# HDSC_HC32L156JX register map
Vendor: HDSC Co.Ltd; Series: ARMCM0P; File version: 1.2
CPU: CM0 r0p0, little endian, no MPU, no FPU, 3 interrupt priority bits
Registers are 8-bit, read-write, reset 0x0 unless marked. A register's access mark holds for its fields unless they carry their own. Offsets are from the block's base; lines under a group give offsets from that group; [hi:lo] are bit positions; {n}, {i} and the like mark numbered series; 'fields as' and 'values as' point back to an identical list; <NAME> marks a mode.

## Memory map
0x40000000 FLASH size 0x10C
0x40000200 UID size 0xC
0x40010000 CLOCK size 0x69
0x40011000 HWWDT size 0x18
0x40012000 SWWDT size 0xC04
0x40015000 DTIM1 size 0x1C — desc DTIM
0x40015020 DTIM2 size 0x1C — desc DTIM
0x40025000 CT0_PPG size 0x12 — desc CT_PPG
0x40025000 CT0_PWC size 0x12 — desc CT_PWC
0x40025000 CT0_PWM size 0x12 — desc CT_PWM
0x40025000 CT0_RT size 0x12 — desc CT_RT
0x40025040 CT1_PPG size 0x12 — desc CT_PPG
0x40025040 CT1_PWC size 0x12 — desc CT_PWC
0x40025040 CT1_PWM size 0x12 — desc CT_PWM
0x40025040 CT1_RT size 0x12 — desc CT_RT
0x40025080 CT2_PPG size 0x12 — desc CT_PPG
0x40025080 CT2_PWC size 0x12 — desc CT_PWC
0x40025080 CT2_PWM size 0x12 — desc CT_PWM
0x40025080 CT2_RT size 0x12 — desc CT_RT
0x400250C0 CT3_PPG size 0x12 — desc CT_PPG
0x400250C0 CT3_PWC size 0x12 — desc CT_PWC
0x400250C0 CT3_PWM size 0x12 — desc CT_PWM
0x400250C0 CT3_RT size 0x12 — desc CT_RT
0x40025100 CTIOSEL03 size 0x2
0x40025200 CT4_PPG size 0x12 — desc CT_PPG
0x40025200 CT4_PWC size 0x12 — desc CT_PWC
0x40025200 CT4_PWM size 0x12 — desc CT_PWM
0x40025200 CT4_RT size 0x12 — desc CT_RT
0x40025240 CT5_PPG size 0x12 — desc CT_PPG
0x40025240 CT5_PWC size 0x12 — desc CT_PWC
0x40025240 CT5_PWM size 0x12 — desc CT_PWM
0x40025240 CT5_RT size 0x12 — desc CT_RT
0x40025280 CT6_PPG size 0x12 — desc CT_PPG
0x40025280 CT6_PWC size 0x12 — desc CT_PWC
0x40025280 CT6_PWM size 0x12 — desc CT_PWM
0x40025280 CT6_RT size 0x12 — desc CT_RT
0x400252C0 CT7_PPG size 0x12 — desc CT_PPG
0x400252C0 CT7_PWC size 0x12 — desc CT_PWC
0x400252C0 CT7_PWM size 0x12 — desc CT_PWM
0x400252C0 CT7_RT size 0x12 — desc CT_RT
0x40025300 CTIOSEL47 size 0x2
0x40025F00 SBSSR size 0xFE
0x40027000 ADC size 0x108
0x4002E000 OSC size 0x144
0x40030000 EXTINT size 0x1A
0x40031000 IRQC size 0x94
0x40032000 LCDC size 0x101
0x40033000 GPIO size 0x924
0x40035000 WSUNIT size 0x710
0x40037000 MSC4_I2C size 0x42 — desc MSC_I2C
0x40037000 MSC4_SPI size 0x42 — desc MSC_SPI
0x40037000 MSC4_UART size 0x42 — desc MSC_UART
0x40037100 MSC5_I2C size 0x42 — desc MSC_I2C
0x40037100 MSC5_SPI size 0x42 — desc MSC_SPI
0x40037100 MSC5_UART size 0x42 — desc MSC_UART
0x40037200 MSC6_I2C size 0x42 — desc MSC_I2C
0x40037200 MSC6_SPI size 0x42 — desc MSC_SPI
0x40037200 MSC6_UART size 0x42 — desc MSC_UART
0x40038000 MSC0_I2C size 0x42 — desc MSC_I2C
0x40038000 MSC0_SPI size 0x42 — desc MSC_SPI
0x40038000 MSC0_UART size 0x42 — desc MSC_UART
0x40038100 MSC1_I2C size 0x42 — desc MSC_I2C
0x40038100 MSC1_SPI size 0x42 — desc MSC_SPI
0x40038100 MSC1_UART size 0x42 — desc MSC_UART
0x40038200 MSC2_I2C size 0x42 — desc MSC_I2C
0x40038200 MSC2_SPI size 0x42 — desc MSC_SPI
0x40038200 MSC2_UART size 0x42 — desc MSC_UART
0x4003B000 RTC size 0x31
0x4003C000 PARITY size 0x14
0x4003C100 PCG size 0x28
0x4003C200 BUZZER size 0x5
0x4003C300 VC size 0x74
0x4003C800 SCI size 0x31
0x4006B000 AES size 0x71
0xF8000000 FASTIO size 0x100

## ADC
Base 0x40027000
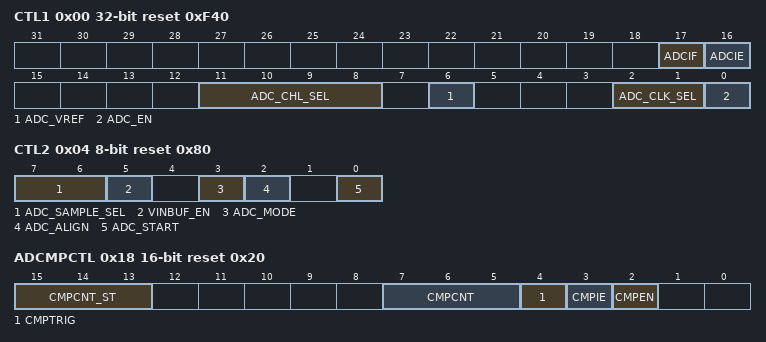
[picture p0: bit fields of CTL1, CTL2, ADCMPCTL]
0x00 CTL1 32-bit reset 0xF40
  [17] ADCIF, [16] ADCIE, [11:8] ADC_CHL_SEL, [6] ADC_VREF, [2:1] ADC_CLK_SEL, [0] ADC_EN
0x04 CTL2 reset 0x80
  [7:6] ADC_SAMPLE_SEL, [5] VINBUF_EN, [3] ADC_MODE, [2] ADC_ALIGN, [0] ADC_START
0x0C RESULT 16-bit ro
0x10 ADCMPIF 32-bit
  [0] CMPIF
0x14 ADCMPF 32-bit ro
  [0] CMPF
0x18 ADCMPCTL 16-bit reset 0x20
  [15:13] CMPCNT_ST ro, [7:5] CMPCNT, [4] CMPTRIG, [3] CMPIE, [2] CMPEN
0x1C ADCMPL 16-bit
  [15:6] CDL
0x1E ADCMPH 16-bit
  [15:6] CDH

## AES
Base 0x4006B000
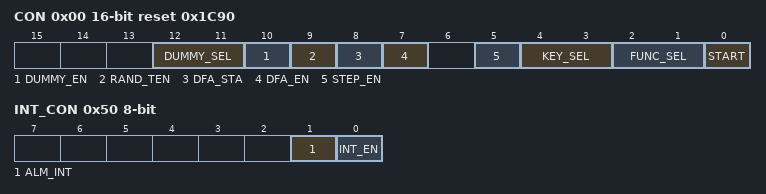
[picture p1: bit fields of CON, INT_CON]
0x00 CON 16-bit reset 0x1C90
  [12:11] DUMMY_SEL, [10] DUMMY_EN, [9] RAND_TEN, [8] DFA_STA ro, [7] DFA_EN, [5] STEP_EN, [4:3] KEY_SEL, [2:1] FUNC_SEL, [0] START
{0x10+4i} DATA{i} 32-bit (i=0..3)
{0x20+4i} KEY{i} 32-bit (i=0..7)
0x40 RNG0 32-bit reset 0x603080D
0x44 RNG1 32-bit reset 0x50A0B04
0x50 INT_CON
  [1] ALM_INT, [0] INT_EN
0x60 DIV_EN
  [0] DIV_EN
